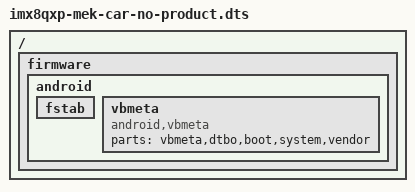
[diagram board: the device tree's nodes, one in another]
/*
 * Copyright 2019 NXP
 *
 * This program is free software; you can redistribute it and/or
 * modify it under the terms of the GNU General Public License
 * as published by the Free Software Foundation; either version 2
 * of the License, or (at your option) any later version.
 *
 * This program is distributed in the hope that it will be useful,
 * but WITHOUT ANY WARRANTY; without even the implied warranty of
 * MERCHANTABILITY or FITNESS FOR A PARTICULAR PURPOSE.  See the
 * GNU General Public License for more details.
 */

#include "imx8qxp-mek-car.dts"

/ {
	firmware {
		android {
			fstab {
				/delete-node/ product;
			};
			vbmeta {
				/*we need use FirstStageMountVBootV2 if we enable avb*/
				compatible = "android,vbmeta";
				/*parts means the partition witch can be mount in first stage*/
				parts = "vbmeta,dtbo,boot,system,vendor";
			};
		};
	};
};
